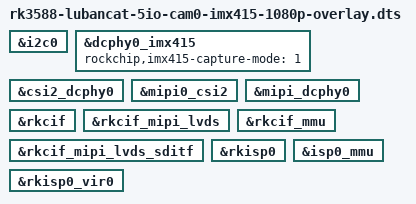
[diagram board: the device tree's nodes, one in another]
/dts-v1/;
/plugin/;

#include <dt-bindings/usb/pd.h>
#include <dt-bindings/gpio/gpio.h>
#include <dt-bindings/pwm/pwm.h>
#include <dt-bindings/pinctrl/rockchip.h>
#include <dt-bindings/input/rk-input.h>
#include <dt-bindings/display/drm_mipi_dsi.h>
#include <dt-bindings/display/rockchip_vop.h>
#include <dt-bindings/sensor-dev.h>

/ {
/* Link path: sensor->csi2_dphy1->mipi2_csi2->rkcif_mipi_lvds2--->rkcif_mipi_lvds2_sditf->rkisp0_vir2 */
	fragment@0 {
		target = <&i2c0>;
		__overlay__ {
			status = "okay";
		};
	};

	fragment@1 {
		target = <&dcphy0_imx415>;
		__overlay__ {
			status = "okay";
			rockchip,imx415-capture-mode=<1>;
		};
	};

	fragment@2 {
		target = <&csi2_dcphy0>;

		__overlay__ {
			status = "okay";
		};
	};

	fragment@3 {
		target = <&mipi0_csi2>;

		__overlay__ {
			status = "okay";
		};
	};

	fragment@4 {
		target = <&mipi_dcphy0>;

		__overlay__ {
			status = "okay";
		};
	};

	fragment@5 {
		target = <&rkcif>;

		__overlay__ {
			status = "okay";
		};
	};

	fragment@6 {
		target = <&rkcif_mipi_lvds>;

		__overlay__ {
			status = "okay";
		};
	};

	fragment@7 {
		target = <&rkcif_mipi_lvds_sditf>;

		__overlay__ {
			status = "okay";
		};
	};

	fragment@8 {
		target = <&rkcif_mmu>;

		__overlay__ {
			status = "okay";
		};
	};

	fragment@9 {
		target = <&rkisp0>;

		__overlay__ {
			status = "okay";
		};
	};

	fragment@10 {
		target = <&isp0_mmu>;

		__overlay__ {
			status = "okay";
		};
	};

	fragment@11 {
		target = <&rkisp0_vir0>;

		__overlay__ {
			status = "okay";
		};
	};
};

